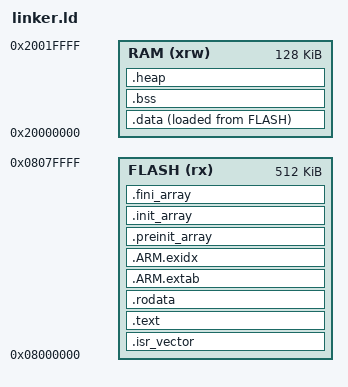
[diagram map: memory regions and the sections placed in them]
/*
 * STM32F411VEHx linker script.
 *
 * Memory sizes and the core section layout are adapted from STMicroelectronics'
 * STM32F411VEHX_FLASH.ld in STM32CubeF4 commit
 * 60c8abe0ae88a23bbd1c925358330031e36dd20f.
 *
 * Copyright (c) 2022 STMicroelectronics.
 * SPDX-License-Identifier: Apache-2.0
 */

ENTRY(Reset_Handler)

MEMORY
{
    FLASH (rx)  : ORIGIN = 0x08000000, LENGTH = 512K
    RAM   (xrw) : ORIGIN = 0x20000000, LENGTH = 128K
}

__stack_size = DEFINED(__stack_size) ? __stack_size : 0x400;
__heap_size  = DEFINED(__heap_size) ? __heap_size : 0x200;

_estack = ORIGIN(RAM) + LENGTH(RAM);

SECTIONS
{
    .isr_vector :
    {
        . = ALIGN(4);
        KEEP(*(.isr_vector))
        . = ALIGN(4);
    } > FLASH

    .text :
    {
        . = ALIGN(4);
        *(.text)
        *(.text*)
        *(.glue_7)
        *(.glue_7t)
        KEEP(*(.init))
        KEEP(*(.fini))
        . = ALIGN(4);
        _etext = .;
    } > FLASH

    .rodata :
    {
        . = ALIGN(4);
        *(.rodata)
        *(.rodata*)
        . = ALIGN(4);
    } > FLASH

    .ARM.extab :
    {
        . = ALIGN(4);
        *(.ARM.extab* .gnu.linkonce.armextab.*)
        . = ALIGN(4);
    } > FLASH

    .ARM.exidx :
    {
        . = ALIGN(4);
        __exidx_start = .;
        *(.ARM.exidx*)
        __exidx_end = .;
        . = ALIGN(4);
    } > FLASH

    .preinit_array :
    {
        . = ALIGN(4);
        PROVIDE_HIDDEN(__preinit_array_start = .);
        KEEP(*(.preinit_array*))
        PROVIDE_HIDDEN(__preinit_array_end = .);
        . = ALIGN(4);
    } > FLASH

    .init_array :
    {
        . = ALIGN(4);
        PROVIDE_HIDDEN(__init_array_start = .);
        KEEP(*(SORT(.init_array.*)))
        KEEP(*(.init_array*))
        PROVIDE_HIDDEN(__init_array_end = .);
        . = ALIGN(4);
    } > FLASH

    .fini_array :
    {
        . = ALIGN(4);
        PROVIDE_HIDDEN(__fini_array_start = .);
        KEEP(*(SORT(.fini_array.*)))
        KEEP(*(.fini_array*))
        PROVIDE_HIDDEN(__fini_array_end = .);
        . = ALIGN(4);
    } > FLASH

    _sidata = LOADADDR(.data);

    .data :
    {
        . = ALIGN(4);
        _sdata = .;
        *(.data)
        *(.data*)
        *(.RamFunc)
        *(.RamFunc*)
        . = ALIGN(4);
        _edata = .;
    } > RAM AT > FLASH

    .bss (NOLOAD) :
    {
        . = ALIGN(4);
        _sbss = .;
        __bss_start__ = _sbss;
        *(.bss)
        *(.bss*)
        *(COMMON)
        . = ALIGN(4);
        _ebss = .;
        __bss_end__ = _ebss;
    } > RAM

    .heap (NOLOAD) :
    {
        . = ALIGN(8);
        _sheap = .;
        . = . + __heap_size;
        . = ALIGN(8);
        _eheap = .;
        PROVIDE(end = .);
        PROVIDE(_end = .);
    } > RAM

    _stack_limit = _estack - __stack_size;

    PROVIDE(__StackTop = _estack);
    PROVIDE(__StackLimit = _stack_limit);

    ASSERT(_eheap <= _stack_limit, "RAM overflow: heap and static data overlap the main stack")

    .ARM.attributes 0 :
    {
        *(.ARM.attributes)
    }
}
